# bao1x register map
Vendor: baochip; File version: 1.0
Registers are 32-bit, read-write, reset 0x0 unless marked. A register's access mark holds for its fields unless they carry their own. Offsets are from the block's base; [hi:lo] are bit positions; {n}, {i} and the like mark numbered series; <NAME> marks a mode.

## IOX
Base 0x5012F000
{0x0+4i} SFR_AFSEL_CRAFSEL{i} (i=0..11) — See `iox.sv#L73 <https://github.com/baochip/baochip-1x/blob/main/rtl/modules/ifs ub/rtl/iox.sv#L73>`__ (line numbers are approximate)
  [15:0] crafsel{i} — crafsel read/write control register
{0x100+4i} SFR_INTCR_CRINT{i} (i=0..7) — See `iox.sv#L127 <https://github.com/baochip/baochip-1x/blob/main/rtl/modules/if sub/rtl/iox.sv#L127>`__ (line numbers are approximate)
  [9:0] crint{i} — crint read/write control register
0x120 SFR_INTFR — See `iox.sv#L128 <https://github.com/baochip/baochip-1x/blob/main/rtl/modules/if sub/rtl/iox.sv#L128>`__ (line numbers are approximate)
  [7:0] frint — frint flag register. `1` means event happened, write back `1` in respective bit position to clear the flag
{0x130+4i} SFR_GPIOOUT_CRGO{i} (i=0..5) — See `iox.sv#L146 <https://github.com/baochip/baochip-1x/blob/main/rtl/modules/if sub/rtl/iox.sv#L146>`__ (line numbers are approximate)
  [15:0] crgo{i} — crgo read/write control register
{0x148+4i} SFR_GPIOOE_CRGOE{i} (i=0..5) — See `iox.sv#L147 <https://github.com/baochip/baochip-1x/blob/main/rtl/modules/if sub/rtl/iox.sv#L147>`__ (line numbers are approximate)
  [15:0] crgoe{i} — crgoe read/write control register
{0x160+4i} SFR_GPIOPU_CRGPU{i} (i=0..5) — See `iox.sv#L148 <https://github.com/baochip/baochip-1x/blob/main/rtl/modules/if sub/rtl/iox.sv#L148>`__ (line numbers are approximate)
  [15:0] crgpu{i} — crgpu read/write control register
{0x178+4i} SFR_GPIOIN_SRGI{i} (i=0..5) — See `iox.sv#L149 <https://github.com/baochip/baochip-1x/blob/main/rtl/modules/if sub/rtl/iox.sv#L149>`__ (line numbers are approximate)
  [15:0] srgi{i} — srgi read only status register
0x200 SFR_PIOSEL — See `iox.sv#L249 <https://github.com/baochip/baochip-1x/blob/main/rtl/modules/if sub/rtl/iox.sv#L249>`__ (line numbers are approximate)
  [31:0] piosel — piosel read/write control register
{0x230+4i} SFR_CFG_SCHM_CR_CFG_SCHMSEL{i} (i=0..5) — See `iox.sv#L225 <https://github.com/baochip/baochip-1x/blob/main/rtl/modules/if sub/rtl/iox.sv#L225>`__ (line numbers are approximate)
  [15:0] cr_cfg_schmsel{i} — cr_cfg_schmsel read/write control register
{0x248+4i} SFR_CFG_SLEW_CR_CFG_SLEWSLOW{i} (i=0..5) — See `iox.sv#L226 <https://github.com/baochip/baochip-1x/blob/main/rtl/modules/if sub/rtl/iox.sv#L226>`__ (line numbers are approximate)
  [15:0] cr_cfg_slewslow{i} — cr_cfg_slewslow read/write control register
{0x260+4i} SFR_CFG_DRVSEL_CR_CFG_DRVSEL{i} (i=0..5) — See `iox.sv#L227 <https://github.com/baochip/baochip-1x/blob/main/rtl/modules/if sub/rtl/iox.sv#L227>`__ (line numbers are approximate)
  [31:0] cr_cfg_drvsel{i} — cr_cfg_drvsel read/write control register

## PWM
Base 0x50120000
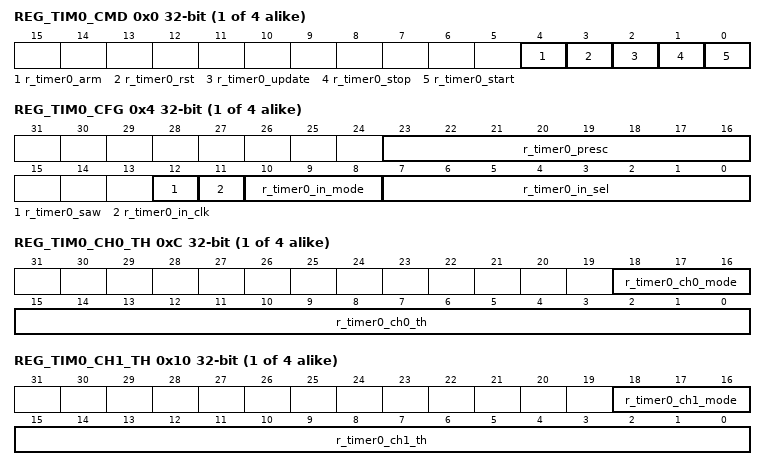
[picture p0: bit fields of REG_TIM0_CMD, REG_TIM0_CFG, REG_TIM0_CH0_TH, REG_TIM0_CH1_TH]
{0x0+0x40*i} REG_TIM{i}_CMD (i=0..3) — See `adv_timer_apb_if.sv <https://github.com/baochip/baochip-1x/blob/main/rtl/ip s/apb/apb_adv_timer/rtl/adv_timer_apb_if.sv>`__
  [4] r_timer{i}_arm, [3] r_timer{i}_rst, [2] r_timer{i}_update, [1] r_timer{i}_stop, [0] r_timer{i}_start
{0x4+0x40*i} REG_TIM{i}_CFG (i=0..3) — See `adv_timer_apb_if.sv <https://github.com/baochip/baochip-1x/blob/main/rtl/ip s/apb/apb_adv_timer/rtl/adv_timer_apb_if.sv>`__
  [23:16] r_timer{i}_presc, [12] r_timer{i}_saw, [11] r_timer{i}_in_clk, [10:8] r_timer{i}_in_mode, [7:0] r_timer{i}_in_sel
{0xC+0x40*i} REG_TIM{i}_CH0_TH (i=0..3) — See `adv_timer_apb_if.sv <https://github.com/baochip/baochip-1x/blob/main/rtl/ip s/apb/apb_adv_timer/rtl/adv_timer_apb_if.sv>`__
  [18:16] r_timer{i}_ch0_mode, [15:0] r_timer{i}_ch0_th
{0x10+0x40*i} REG_TIM{i}_CH1_TH (i=0..3) — See `adv_timer_apb_if.sv <https://github.com/baochip/baochip-1x/blob/main/rtl/ip s/apb/apb_adv_timer/rtl/adv_timer_apb_if.sv>`__
  [18:16] r_timer{i}_ch1_mode, [15:0] r_timer{i}_ch1_th
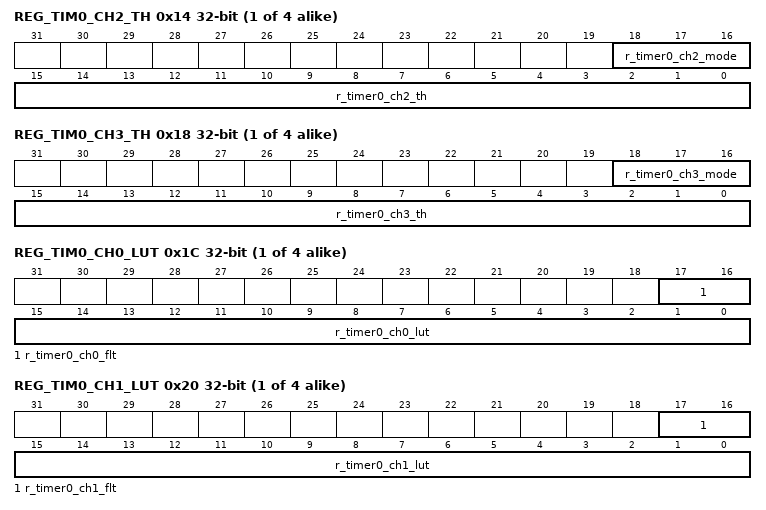
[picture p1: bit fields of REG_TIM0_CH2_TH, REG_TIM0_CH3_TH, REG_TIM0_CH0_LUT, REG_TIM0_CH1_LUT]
{0x14+0x40*i} REG_TIM{i}_CH2_TH (i=0..3) — See `adv_timer_apb_if.sv <https://github.com/baochip/baochip-1x/blob/main/rtl/ip s/apb/apb_adv_timer/rtl/adv_timer_apb_if.sv>`__
  [18:16] r_timer{i}_ch2_mode, [15:0] r_timer{i}_ch2_th
{0x18+0x40*i} REG_TIM{i}_CH3_TH (i=0..3) — See `adv_timer_apb_if.sv <https://github.com/baochip/baochip-1x/blob/main/rtl/ip s/apb/apb_adv_timer/rtl/adv_timer_apb_if.sv>`__
  [18:16] r_timer{i}_ch3_mode, [15:0] r_timer{i}_ch3_th
{0x1C+0x40*i} REG_TIM{i}_CH0_LUT (i=0..3) — See `adv_timer_apb_if.sv <https://github.com/baochip/baochip-1x/blob/main/rtl/ip s/apb/apb_adv_timer/rtl/adv_timer_apb_if.sv>`__
  [17:16] r_timer{i}_ch0_flt, [15:0] r_timer{i}_ch0_lut
{0x20+0x40*i} REG_TIM{i}_CH1_LUT (i=0..3) — See `adv_timer_apb_if.sv <https://github.com/baochip/baochip-1x/blob/main/rtl/ip s/apb/apb_adv_timer/rtl/adv_timer_apb_if.sv>`__
  [17:16] r_timer{i}_ch1_flt, [15:0] r_timer{i}_ch1_lut
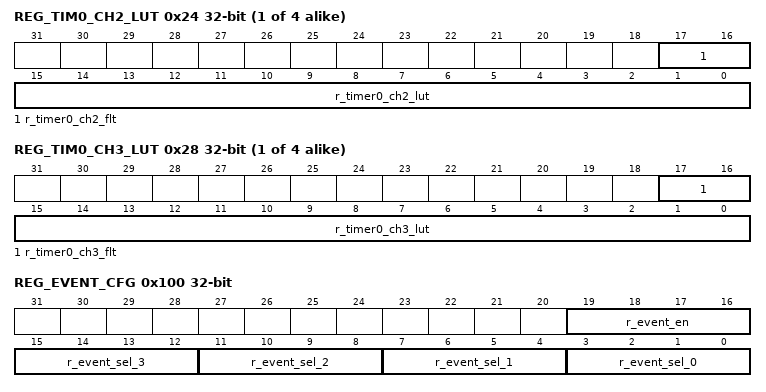
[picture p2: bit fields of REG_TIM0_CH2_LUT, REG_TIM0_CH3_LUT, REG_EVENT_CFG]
{0x24+0x40*i} REG_TIM{i}_CH2_LUT (i=0..3) — See `adv_timer_apb_if.sv <https://github.com/baochip/baochip-1x/blob/main/rtl/ip s/apb/apb_adv_timer/rtl/adv_timer_apb_if.sv>`__
  [17:16] r_timer{i}_ch2_flt, [15:0] r_timer{i}_ch2_lut
{0x28+0x40*i} REG_TIM{i}_CH3_LUT (i=0..3) — See `adv_timer_apb_if.sv <https://github.com/baochip/baochip-1x/blob/main/rtl/ip s/apb/apb_adv_timer/rtl/adv_timer_apb_if.sv>`__
  [17:16] r_timer{i}_ch3_flt, [15:0] r_timer{i}_ch3_lut
0x100 REG_EVENT_CFG — See `adv_timer_apb_if.sv <https://github.com/baochip/baochip-1x/blob/main/rtl/ip s/apb/apb_adv_timer/rtl/adv_timer_apb_if.sv>`__
  [19:16] r_event_en, [4n+3:4n] r_event_sel_{n} (n=0..3)
0x104 REG_CH_EN — See `adv_timer_apb_if.sv <https://github.com/baochip/baochip-1x/blob/main/rtl/ip s/apb/apb_adv_timer/rtl/adv_timer_apb_if.sv>`__
  [3:0] r_clk_en
{0x140+4i} REG_PREFD{i} (i=0..3) — See `adv_timer_apb_if.sv <https://github.com/baochip/baochip-1x/blob/main/rtl/ip s/apb/apb_adv_timer/rtl/adv_timer_apb_if.sv>`__
  [9:0] lsclk_prefd_{i}
